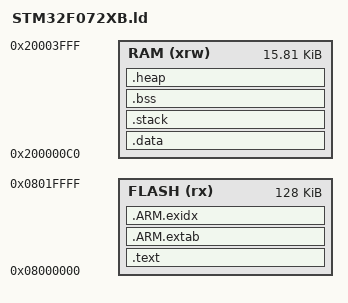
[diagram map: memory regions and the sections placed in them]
/* Linker script to configure memory regions. */

#if !defined(MBED_BOOT_STACK_SIZE)
    #define MBED_BOOT_STACK_SIZE 0x400
#endif

StackSize = MBED_BOOT_STACK_SIZE;

MEMORY
{ 
  FLASH (rx)      : ORIGIN = 0x08000000, LENGTH = 128k
  RAM (xrw)       : ORIGIN = 0x200000C0, LENGTH = 16k - 0x0C0
}

/* Linker script to place sections and symbol values. Should be used together
 * with other linker script that defines memory regions FLASH and RAM.
 * It references following symbols, which must be defined in code:
 *   Reset_Handler : Entry of reset handler
 * 
 * It defines following symbols, which code can use without definition:
 *   __exidx_start
 *   __exidx_end
 *   __etext
 *   __data_start__
 *   __preinit_array_start
 *   __preinit_array_end
 *   __init_array_start
 *   __init_array_end
 *   __fini_array_start
 *   __fini_array_end
 *   __data_end__
 *   __bss_start__
 *   __bss_end__
 *   __end__
 *   end
 *   __HeapLimit
 *   __StackLimit
 *   __StackTop
 *   __stack
 *   _estack
 */
ENTRY(Reset_Handler)

SECTIONS
{
    .text :
    {
        KEEP(*(.isr_vector))
        *(.text*)
        KEEP(*(.init))
        KEEP(*(.fini))

        /* .ctors */
        *crtbegin.o(.ctors)
        *crtbegin?.o(.ctors)
        *(EXCLUDE_FILE(*crtend?.o *crtend.o) .ctors)
        *(SORT(.ctors.*))
        *(.ctors)

        /* .dtors */
        *crtbegin.o(.dtors)
        *crtbegin?.o(.dtors)
        *(EXCLUDE_FILE(*crtend?.o *crtend.o) .dtors)
        *(SORT(.dtors.*))
        *(.dtors)

        *(.rodata*)

        KEEP(*(.eh_frame*))
    } > FLASH

    .ARM.extab :
    {
        *(.ARM.extab* .gnu.linkonce.armextab.*)
    } > FLASH

    __exidx_start = .;
    .ARM.exidx :
    {
        *(.ARM.exidx* .gnu.linkonce.armexidx.*)
    } > FLASH
    __exidx_end = .;

    __etext = .;
    _sidata = .;

    .data : AT (__etext)
    {
        __data_start__ = .;
        _sdata = .;
        *(vtable)
        *(.data*)

        . = ALIGN(8);
        /* preinit data */
        PROVIDE_HIDDEN (__preinit_array_start = .);
        KEEP(*(.preinit_array))
        PROVIDE_HIDDEN (__preinit_array_end = .);

        . = ALIGN(8);
        /* init data */
        PROVIDE_HIDDEN (__init_array_start = .);
        KEEP(*(SORT(.init_array.*)))
        KEEP(*(.init_array))
        PROVIDE_HIDDEN (__init_array_end = .);


        . = ALIGN(8);
        /* finit data */
        PROVIDE_HIDDEN (__fini_array_start = .);
        KEEP(*(SORT(.fini_array.*)))
        KEEP(*(.fini_array))
        PROVIDE_HIDDEN (__fini_array_end = .);

        KEEP(*(.jcr*))
        . = ALIGN(8);
        /* All data end */
        __data_end__ = .;
        _edata = .;

    } > RAM

    /* .stack section doesn't contains any symbols. It is only
     * used for linker to reserve space for the main stack section
     */
    .stack (NOLOAD):
    {
        __StackLimit = .;
        *(.stack*);
        . += StackSize - (. - __StackLimit);
    } > RAM
    __StackTop = ADDR(.stack) + StackSize;
    _estack = __StackTop;
    __StackLimit = ADDR(.stack);
    PROVIDE(__stack = __StackTop);

    .bss :
    {
        . = ALIGN(8);
        __bss_start__ = .;
        _sbss = .;
        *(.bss*)
        *(COMMON)
        . = ALIGN(8);
        __bss_end__ = .;
        _ebss = .;
    } > RAM

    .heap (COPY):
    {
        __end__ = .;
        end = __end__;
        *(.heap*);
        . += (ORIGIN(RAM) + LENGTH(RAM) - .);
        __HeapLimit = .;
    } > RAM

    PROVIDE(__heap_size = SIZEOF(.heap));
    PROVIDE(__mbed_sbrk_start = ADDR(.heap));
    PROVIDE(__mbed_krbs_start = ADDR(.heap) + SIZEOF(.heap));

}
